# USB0_VBP2AHB_WRAP_CONTROLLER_VBP_USB3_CORE_INTR register map
Vendor: Texas Instruments
Peripheral module from a debugger description file (folder am62P).
Registers are 32-bit, read-write, reset values left out (the file's numbers can be read two ways) unless marked. A register's access mark holds for its fields unless they carry their own. Offsets are as the file gives them; lines under a group give offsets from that group; [hi:lo] are bit positions; {n}, {i} and the like mark numbered series; 'fields as' and 'values as' point back to an identical list; <NAME> marks a mode.

## USB0_VBP2AHB_WRAP_CONTROLLER_VBP_USB3_CORE_INTR
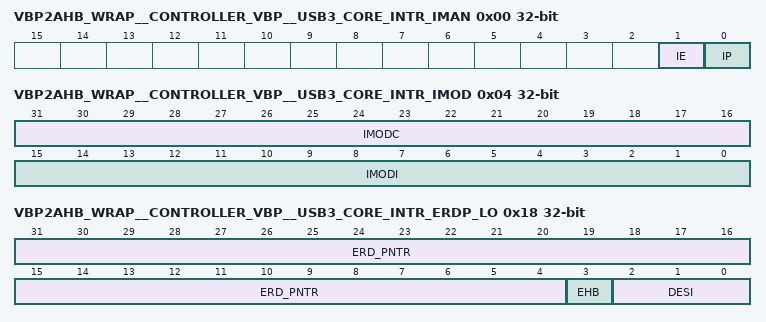
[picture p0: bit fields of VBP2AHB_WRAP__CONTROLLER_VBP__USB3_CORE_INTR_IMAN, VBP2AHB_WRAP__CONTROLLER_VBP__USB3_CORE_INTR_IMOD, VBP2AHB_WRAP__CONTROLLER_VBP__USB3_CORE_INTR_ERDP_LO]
0x00 VBP2AHB_WRAP__CONTROLLER_VBP__USB3_CORE_INTR_IMAN access not given — Interrupter Management Register Bit Definitions For a description of this standard USB register field, see the eXtensible Host Controller Interface for Universal Serial Bus (USB) Specification 3.0.
  [1] IE rw — IE For a description of this standard USB register field, see the eXtensible Host Controller Interface for Universal Serial Bus [USB] Specification 3.0.
  [0] IP — IP Interrupt Pending For a description of this standard USB register field, see the eXtensible Host Controller Interface for Universal Serial Bus [USB] Specification 3.0. (access R/W1TC)
0x04 VBP2AHB_WRAP__CONTROLLER_VBP__USB3_CORE_INTR_IMOD — Interrupter Moderation Register The software may use this register to pace (or even out) the delivery of interrupts to the host CPU. This register provides a guaranteed inter-interrupt delay between interrupts asserted by the xHC, regardless of USB traffic conditions. To independently validate configuration settings, software may use the following algorithm to convert the inter-interrupt Interval value to the common 'interrupts/sec' performance metric.
  [31:16] IMODC — Interrupt Moderation Counter [IMODC] - RW. Default = undefined. Down counter. Loaded with the IMODI value whenever IP is cleared to '0', counts down to '0', and stops. The associated interrupt is signaled whenever this counter is '0', the Event Ring is not empty, the IE and IP flags = '1', and EHB = '0'. This counter may be directly written by software at any time to alter the interrupt rate.
  [15:0] IMODI — Interrupt Moderation Interval [IMODI] - RW. Default = '4000' [~1ms]. Minimum inter-interrupt interval. The interval is specified in 250ns increments. A value of '0' disables interrupt throttling logic and interrupts is generated immediately if IP = '0', EHB = '0', and the Event Ring is not empty.
0x08 VBP2AHB_WRAP__CONTROLLER_VBP__USB3_CORE_INTR_ERSTSZ — Event Ring Segment Table Size Register Bit Definitions For a description of this standard USB register field, see the eXtensible Host Controller Interface for Universal Serial Bus (USB) Specification 3.0.
  [15:0] ERS_TABLE_SIZE — ERS_TABLE_SIZE For a description of this standard USB register field, see the eXtensible Host Controller Interface for Universal Serial Bus [USB] Specification 3.0.
0x0C VBP2AHB_WRAP__CONTROLLER_VBP__USB3_CORE_INTR_RsvdP access not given — RsvdP
0x10 VBP2AHB_WRAP__CONTROLLER_VBP__USB3_CORE_INTR_ERSTBA_LO — ERSTBA_LO
  [31:6] ERS_TABLE_BAR
0x14 VBP2AHB_WRAP__CONTROLLER_VBP__USB3_CORE_INTR_ERSTBA_HI — ERSTBA_HI
  [31:0] ERS_TABLE_BAR — ERS_TABLE_BAR For a description of this standard USB register field, see the eXtensible Host Controller Interface for Universal Serial Bus [USB] Specification 3.0.
0x18 VBP2AHB_WRAP__CONTROLLER_VBP__USB3_CORE_INTR_ERDP_LO access not given — ERDP_LO For a description of this standard USB register field, see the eXtensible Host Controller Interface for Universal Serial Bus (USB) Specification 3.0.
  [31:4] ERD_PNTR rw — ERD_PNTR For a description of this standard USB register field, see the eXtensible Host Controller Interface for Universal Serial Bus [USB] Specification 3.0.
  [3] EHB — HC OS Owned SemaphoreERS_TABLE_SIZEHC BIOS Owned Semaphore USB SMI Enable SMI on Host System Error Enable - SMI on OS Ownership Enable - SMI on PCI Command Enable - SMI on BAR Enable - SMI on Event Interrupt - SMI on Host System Error - SMI on OS Ownership Change - SMI on PCI Command - SMI on BAR - Compatible Port Count - HC OS Owned Semaphore - HC BIOS Owned Semaphore - USB SMI Enable - SMI on Host System Error Enable - SMI on OS Ownership Enable - SMI on PCI Command Enable - SMI on BAR Enable - SMI on Event Interrupt - SMI on Host System Error - SMI on OS Ownership Change - SMI on PCI Command - SMI on BAR - Compatible Port Count (access R/W1TC)
  [2:0] DESI rw — DESI - For a description of this standard USB register field, see the eXtensible Host Controller Interface for Universal Serial Bus [USB] Specification 3.0.
0x1C VBP2AHB_WRAP__CONTROLLER_VBP__USB3_CORE_INTR_ERDP_HI — ERDP_HI
  [31:0] ERD_PNTR — ERD_PNTR For a description of this standard USB register field, see the eXtensible Host Controller Interface for Universal Serial Bus [USB] Specification 3.0.
